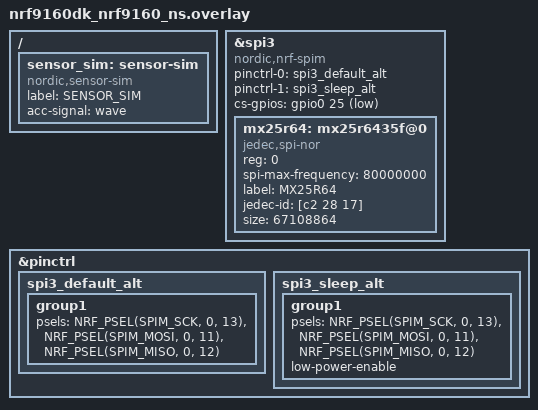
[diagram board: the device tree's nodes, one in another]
/*
 * Copyright (c) 2021 Nordic Semiconductor ASA
 *
 * SPDX-License-Identifier: LicenseRef-Nordic-5-Clause
 */

/ {
	sensor_sim: sensor-sim {
		compatible = "nordic,sensor-sim";
		label = "SENSOR_SIM";
		acc-signal = "wave";
	};
};

&spi3 {
	compatible = "nordic,nrf-spim";
	status = "okay";
	pinctrl-0 = <&spi3_default_alt>;
	pinctrl-1 = <&spi3_sleep_alt>;
	pinctrl-names = "default", "sleep";
	cs-gpios = <&gpio0 25 GPIO_ACTIVE_LOW>;
	mx25r64: mx25r6435f@0 {
		compatible = "jedec,spi-nor";
		reg = <0>;
		spi-max-frequency = <80000000>;
		label = "MX25R64";
		jedec-id = [c2 28 17];
		size = <67108864>;
	};
};

&pinctrl {
	spi3_default_alt: spi3_default_alt {
		group1 {
			psels = <NRF_PSEL(SPIM_SCK, 0, 13)>,
				<NRF_PSEL(SPIM_MOSI, 0, 11)>,
				<NRF_PSEL(SPIM_MISO, 0, 12)>;
		};
	};

	spi3_sleep_alt: spi3_sleep_alt {
		group1 {
			psels = <NRF_PSEL(SPIM_SCK, 0, 13)>,
				<NRF_PSEL(SPIM_MOSI, 0, 11)>,
				<NRF_PSEL(SPIM_MISO, 0, 12)>;
			low-power-enable;
		};
	};
};
